# ATxmega128A1U device description
Architecture: AVR8_XMEGA; Family: AVR XMEGA
Registers are 8-bit, access not given, no defined reset value unless marked. A register's access mark holds for its fields unless they carry their own. Offsets are from the block's base; [hi:lo] are bit positions; {n}, {i} and the like mark numbered series.

## GPIO — General Purpose IO Registers
Instances: GPIO 0x0000
{0x0+i} GPIOR{i} (i=0..9) — General Purpose IO Register {i}
0x0A GPIORA — General Purpose IO Register 10
0x0B GPIORB — General Purpose IO Register 11
0x0C GPIORC — General Purpose IO Register 12
0x0D GPIORD — General Purpose IO Register 13
0x0E GPIORE — General Purpose IO Register 14
0x0F GPIORF — General Purpose IO Register 15

## VPORT — Virtual Port
Instances: VPORT{n} {0x10+4n} (n=0..3)
0x00 DIR — I/O Port Data Direction
0x01 OUT — I/O Port Output
0x02 IN — I/O Port Input
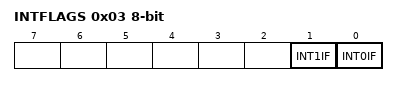
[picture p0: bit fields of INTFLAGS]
0x03 INTFLAGS — Interrupt Flag Register
  [1] INT1IF — Port Interrupt 1 Flag
  [0] INT0IF — Port Interrupt 0 Flag

## OCD (XOCD module) — On-Chip Debug System
Instances: OCD 0x002E
0x00 OCDR0 — OCD Register 0
  [7:0] OCDRD — OCDR Dirty
0x01 OCDR1 — OCD Register 1
  [0] OCDRD — OCDR Dirty

## CPU — CPU registers
Instances: CPU 0x0030
Parameters: CORE_VERSION=V3XJ
0x04 CCP — Configuration Change Protection
  [7:0] CCP — CCP signature
    157=SPM (SPM Instruction Protection); 216=IOREG (IO Register Protection)
0x08 RAMPD
0x09 RAMPX
0x0A RAMPY
0x0B RAMPZ
0x0C EIND — Extended Indirect Jump
0x0D SPL — Stack Pointer Low
0x0E SPH — Stack Pointer High
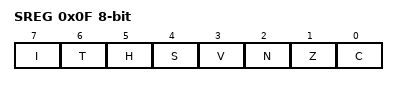
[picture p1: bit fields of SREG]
0x0F SREG — Status Register
  [7] I — Global Interrupt Enable Flag
  [6] T — Transfer Bit
  [5] H — Half Carry Flag
  [4] S — N Exclusive Or V Flag
  [3] V — Two's Complement Overflow Flag
  [2] N — Negative Flag
  [1] Z — Zero Flag
  [0] C — Carry Flag

## CLK — Clock System
Instances: CLK 0x0040
0x00 CTRL — Control Register
  [2:0] SCLKSEL — System Clock Selection
    0=RC2M (Internal 2 MHz RC Oscillator); 1=RC32M (Internal 32 MHz RC Oscillator); 2=RC32K (Internal 32.768 kHz RC Oscillator); 3=XOSC (External Crystal Oscillator or Clock); 4=PLL (Phase Locked Loop)
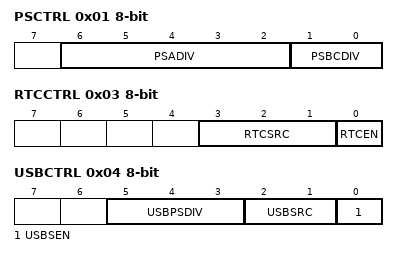
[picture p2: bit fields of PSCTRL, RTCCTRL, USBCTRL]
0x01 PSCTRL — Prescaler Control Register
  [6:2] PSADIV — Prescaler A Division Factor
    0=Divide by 1; 1=Divide by 2; 3=Divide by 4; 5=Divide by 8; 7=Divide by 16; 9=Divide by 32; 11=Divide by 64; 13=Divide by 128; 15=Divide by 256; 17=Divide by 512
  [1:0] PSBCDIV — Prescaler B and C Division factor
    0=Divide B by 1 and C by 1; 1=1_2 (Divide B by 1 and C by 2); 2=4_1 (Divide B by 4 and C by 1); 3=2_2 (Divide B by 2 and C by 2)
0x02 LOCK
  [0] LOCK — Clock System Lock
0x03 RTCCTRL — RTC Control Register
  [3:1] RTCSRC — Clock Source
    0=ULP (1.024 kHz from internal 32kHz ULP); 1=TOSC (1.024 kHz from 32.768 kHz crystal oscillator on TOSC); 2=RCOSC (1.024 kHz from internal 32.768 kHz RC oscillator); 5=TOSC32 (32.768 kHz from 32.768 kHz crystal oscillator on TOSC); 6=RCOSC32 (32.768 kHz from internal 32.768 kHz RC oscillator); 7=EXTCLK (External Clock from TOSC1)
  [0] RTCEN — Clock Source Enable
0x04 USBCTRL — USB Control Register
  [5:3] USBPSDIV — Prescaler Division Factor
    0=Divide by 1; 1=Divide by 2; 2=Divide by 4; 3=Divide by 8; 4=Divide by 16; 5=Divide by 32
  [2:1] USBSRC — Clock Source
    0=PLL; 1=RC32M (Internal 32 MHz RC Oscillator)
  [0] USBSEN — Clock Source Enable

## PR — Power Reduction
Instances: PR 0x0070
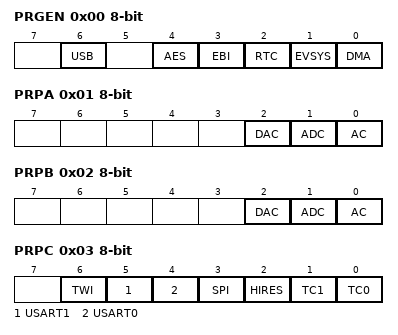
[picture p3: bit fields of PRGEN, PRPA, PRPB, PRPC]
0x00 PRGEN — General Power Reduction
  [6] USB
  [4] AES
  [3] EBI — External Bus Interface
  [2] RTC — Real-time Counter
  [1] EVSYS — Event System
  [0] DMA — DMA-Controller
0x01 PRPA — Power Reduction Port A
  [2] DAC — Port A DAC
  [1] ADC — Port A ADC
  [0] AC — Port A Analog Comparator
0x02 PRPB — Power Reduction Port B
  [2] DAC — Port B DAC
  [1] ADC — Port B ADC
  [0] AC — Port B Analog Comparator
0x03 PRPC — Power Reduction Port C
  [6] TWI — Port C Two-wire Interface
  [5] USART1 — Port C USART1
  [4] USART0 — Port C USART0
  [3] SPI — Port C SPI
  [2] HIRES — Port C AWEX
  [1] TC1 — Port C Timer/Counter1
  [0] TC0 — Port C Timer/Counter0
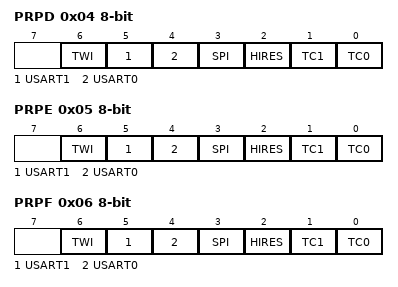
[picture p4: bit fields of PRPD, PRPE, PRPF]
0x04 PRPD — Power Reduction Port D
  [6] TWI — Port D Two-wire Interface
  [5] USART1 — Port D USART1
  [4] USART0 — Port D USART0
  [3] SPI — Port D SPI
  [2] HIRES — Port D AWEX
  [1] TC1 — Port D Timer/Counter1
  [0] TC0 — Port D Timer/Counter0
0x05 PRPE — Power Reduction Port E
  [6] TWI — Port E Two-wire Interface
  [5] USART1 — Port E USART1
  [4] USART0 — Port E USART0
  [3] SPI — Port E SPI
  [2] HIRES — Port E AWEX
  [1] TC1 — Port E Timer/Counter1
  [0] TC0 — Port E Timer/Counter0
0x06 PRPF — Power Reduction Port F
  [6] TWI — Port F Two-wire Interface
  [5] USART1 — Port F USART1
  [4] USART0 — Port F USART0
  [3] SPI — Port F SPI
  [2] HIRES — Port F AWEX
  [1] TC1 — Port F Timer/Counter1
  [0] TC0 — Port F Timer/Counter0
